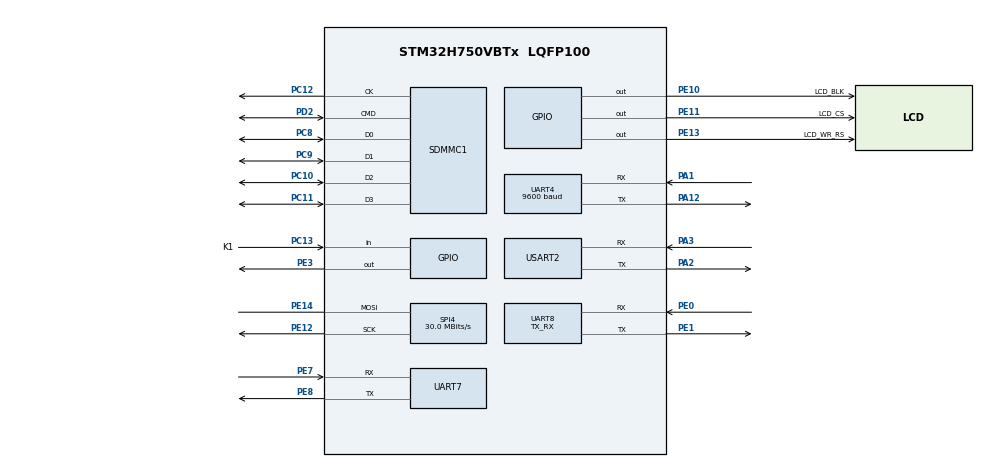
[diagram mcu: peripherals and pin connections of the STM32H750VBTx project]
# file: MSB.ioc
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CORTEX_M7.default_mode_Activation=1
Dma.Request0=UART8_TX
Dma.Request1=UART7_RX
Dma.Request2=UART4_TX
Dma.Request3=USART2_RX
Dma.UART4_TX.2.Direction=DMA_MEMORY_TO_PERIPH
Dma.UART4_TX.2.EventEnable=DISABLE
Dma.UART4_TX.2.FIFOMode=DMA_FIFOMODE_DISABLE
Dma.UART4_TX.2.Instance=DMA1_Stream3
Dma.UART4_TX.2.MemDataAlignment=DMA_MDATAALIGN_BYTE
Dma.UART4_TX.2.MemInc=DMA_MINC_ENABLE
Dma.UART4_TX.2.Mode=DMA_NORMAL
Dma.UART4_TX.2.PeriphDataAlignment=DMA_PDATAALIGN_BYTE
Dma.UART4_TX.2.PeriphInc=DMA_PINC_DISABLE
Dma.UART4_TX.2.Polarity=HAL_DMAMUX_REQ_GEN_RISING
Dma.UART4_TX.2.Priority=DMA_PRIORITY_LOW
Dma.UART4_TX.2.RequestNumber=1
Dma.UART4_TX.2.SignalID=NONE
Dma.UART4_TX.2.SyncEnable=DISABLE
Dma.UART4_TX.2.SyncPolarity=HAL_DMAMUX_SYNC_NO_EVENT
Dma.UART4_TX.2.SyncRequestNumber=1
Dma.UART4_TX.2.SyncSignalID=NONE
Dma.UART7_RX.1.Direction=DMA_PERIPH_TO_MEMORY
Dma.UART7_RX.1.EventEnable=DISABLE
Dma.UART7_RX.1.FIFOMode=DMA_FIFOMODE_DISABLE
Dma.UART7_RX.1.Instance=DMA1_Stream0
Dma.UART7_RX.1.MemDataAlignment=DMA_MDATAALIGN_BYTE
Dma.UART7_RX.1.MemInc=DMA_MINC_ENABLE
Dma.UART7_RX.1.Mode=DMA_CIRCULAR
Dma.UART7_RX.1.PeriphDataAlignment=DMA_PDATAALIGN_BYTE
Dma.UART7_RX.1.PeriphInc=DMA_PINC_DISABLE
Dma.UART7_RX.1.Polarity=HAL_DMAMUX_REQ_GEN_RISING
Dma.UART7_RX.1.Priority=DMA_PRIORITY_LOW
Dma.UART7_RX.1.RequestNumber=1
Dma.UART7_RX.1.SignalID=NONE
Dma.UART7_RX.1.SyncEnable=DISABLE
Dma.UART7_RX.1.SyncPolarity=HAL_DMAMUX_SYNC_NO_EVENT
Dma.UART7_RX.1.SyncRequestNumber=1
Dma.UART7_RX.1.SyncSignalID=NONE
Dma.UART8_TX.0.Direction=DMA_MEMORY_TO_PERIPH
Dma.UART8_TX.0.EventEnable=DISABLE
Dma.UART8_TX.0.FIFOMode=DMA_FIFOMODE_DISABLE
Dma.UART8_TX.0.Instance=DMA1_Stream1
Dma.UART8_TX.0.MemDataAlignment=DMA_MDATAALIGN_BYTE
Dma.UART8_TX.0.MemInc=DMA_MINC_ENABLE
Dma.UART8_TX.0.Mode=DMA_NORMAL
Dma.UART8_TX.0.PeriphDataAlignment=DMA_PDATAALIGN_BYTE
Dma.UART8_TX.0.PeriphInc=DMA_PINC_DISABLE
Dma.UART8_TX.0.Polarity=HAL_DMAMUX_REQ_GEN_RISING
Dma.UART8_TX.0.Priority=DMA_PRIORITY_VERY_HIGH
Dma.UART8_TX.0.RequestNumber=1
Dma.UART8_TX.0.SignalID=NONE
Dma.UART8_TX.0.SyncEnable=DISABLE
Dma.UART8_TX.0.SyncPolarity=HAL_DMAMUX_SYNC_NO_EVENT
Dma.UART8_TX.0.SyncRequestNumber=1
Dma.UART8_TX.0.SyncSignalID=NONE
Dma.USART2_RX.3.Direction=DMA_PERIPH_TO_MEMORY
Dma.USART2_RX.3.EventEnable=DISABLE
Dma.USART2_RX.3.FIFOMode=DMA_FIFOMODE_DISABLE
Dma.USART2_RX.3.Instance=DMA1_Stream2
Dma.USART2_RX.3.MemDataAlignment=DMA_MDATAALIGN_BYTE
Dma.USART2_RX.3.MemInc=DMA_MINC_ENABLE
Dma.USART2_RX.3.Mode=DMA_NORMAL
Dma.USART2_RX.3.PeriphDataAlignment=DMA_PDATAALIGN_BYTE
Dma.USART2_RX.3.PeriphInc=DMA_PINC_DISABLE
Dma.USART2_RX.3.Polarity=HAL_DMAMUX_REQ_GEN_RISING
Dma.USART2_RX.3.Priority=DMA_PRIORITY_LOW
Dma.USART2_RX.3.RequestNumber=1
Dma.USART2_RX.3.SignalID=NONE
Dma.USART2_RX.3.SyncEnable=DISABLE
Dma.USART2_RX.3.SyncPolarity=HAL_DMAMUX_SYNC_NO_EVENT
Dma.USART2_RX.3.SyncRequestNumber=1
Dma.USART2_RX.3.SyncSignalID=NONE
FATFS.USE_DMA_CODE_SD=1
FATFS._CODE_PAGE=936
FATFS._FS_EXFAT=1
FATFS._USE_LFN=2
Mcu.Family=STM32H7
Mcu.Name=STM32H750VBTx
Mcu.Package=LQFP100
NVIC.DMA1_Stream0_IRQn=true\:1\:0\:true\:false\:true\:false\:true\:true
NVIC.DMA1_Stream1_IRQn=true\:1\:1\:true\:false\:true\:false\:true\:true
NVIC.DMA1_Stream2_IRQn=true\:1\:0\:true\:false\:true\:false\:true\:true
NVIC.DMA1_Stream3_IRQn=true\:1\:0\:true\:false\:true\:false\:true\:true
NVIC.PriorityGroup=NVIC_PRIORITYGROUP_3
NVIC.SDMMC1_IRQn=true\:1\:0\:true\:false\:true\:true\:true\:true
NVIC.TIM15_IRQn=true\:1\:0\:true\:false\:true\:true\:true\:true
NVIC.TIM16_IRQn=true\:0\:0\:true\:false\:true\:true\:true\:true
NVIC.TIM17_IRQn=true\:3\:0\:true\:false\:true\:true\:true\:true
NVIC.TIM8_TRG_COM_TIM14_IRQn=true\:2\:0\:true\:false\:true\:true\:true\:true
NVIC.UART4_IRQn=true\:1\:0\:true\:false\:true\:true\:true\:true
NVIC.UART7_IRQn=true\:1\:0\:true\:false\:true\:true\:true\:true
NVIC.UART8_IRQn=true\:5\:0\:true\:false\:true\:false\:true\:true
NVIC.USART2_IRQn=true\:1\:0\:true\:false\:true\:true\:true\:true
PA1.Mode=Asynchronous
PA1.Signal=UART4_RX
PA12.Mode=Asynchronous
PA12.Signal=UART4_TX
PA13\ (JTMS/SWDIO).Mode=Serial_Wire
PA13\ (JTMS/SWDIO).Signal=DEBUG_JTMS-SWDIO
PA14\ (JTCK/SWCLK).Mode=Serial_Wire
PA14\ (JTCK/SWCLK).Signal=DEBUG_JTCK-SWCLK
PA2.Mode=Asynchronous
PA2.Signal=USART2_TX
PA3.Mode=Asynchronous
PA3.Signal=USART2_RX
PC10.Mode=SD_4_bits_Wide_bus
PC10.Signal=SDMMC1_D2
PC11.Mode=SD_4_bits_Wide_bus
PC11.Signal=SDMMC1_D3
PC12.Mode=SD_4_bits_Wide_bus
PC12.Signal=SDMMC1_CK
PC13.GPIO_Label=K1
PC13.GPIO_PuPd=GPIO_PULLDOWN
PC13.Signal=GPIO_Input
PC8.Mode=SD_4_bits_Wide_bus
PC8.Signal=SDMMC1_D0
PC9.Mode=SD_4_bits_Wide_bus
PC9.Signal=SDMMC1_D1
PD2.Mode=SD_4_bits_Wide_bus
PD2.Signal=SDMMC1_CMD
PE0.Mode=Asynchronous
PE0.Signal=UART8_RX
PE1.Mode=Asynchronous
PE1.Signal=UART8_TX
PE10.GPIO_Label=LCD_BLK
PE10.Signal=GPIO_Output
PE11.GPIO_Label=LCD_CS
PE11.Signal=GPIO_Output
PE12.Mode=Simplex_Bidirectional_Master
PE12.Signal=SPI4_SCK
PE13.GPIO_Label=LCD_WR_RS
PE13.Signal=GPIO_Output
PE14.Mode=Simplex_Bidirectional_Master
PE14.Signal=SPI4_MOSI
PE3.Signal=GPIO_Output
PE7.Mode=Asynchronous
PE7.Signal=UART7_RX
PE8.Mode=Asynchronous
PE8.Signal=UART7_TX
PH0-OSC_IN\ (PH0).Mode=HSE-External-Oscillator
PH0-OSC_IN\ (PH0).Signal=RCC_OSC_IN
PH1-OSC_OUT\ (PH1).Mode=HSE-External-Oscillator
PH1-OSC_OUT\ (PH1).Signal=RCC_OSC_OUT
ProjectManager.HeapSize=0x2000
ProjectManager.StackSize=0x8000
ProjectManager.TargetToolchain=CMake
RCC.ADCFreq_Value=50390625
RCC.APB1Freq_Value=120000000
RCC.APB2Freq_Value=120000000
RCC.APB3Freq_Value=120000000
RCC.APB4Freq_Value=120000000
RCC.CortexFreq_Value=480000000
RCC.D1PPRE=RCC_APB3_DIV2
RCC.D2PPRE1=RCC_APB1_DIV2
RCC.D2PPRE2=RCC_APB2_DIV2
RCC.D3PPRE=RCC_APB4_DIV2
RCC.DIVM1=5
RCC.DIVN1=192
RCC.DIVQ1=15
RCC.HCLKFreq_Value=240000000
RCC.HPRE=RCC_HCLK_DIV2
RCC.PLLFRACN=0
RCC.PLLSourceVirtual=RCC_PLLSOURCE_HSE
RCC.SYSCLKFreq_VALUE=480000000
RCC.SYSCLKSource=RCC_SYSCLKSOURCE_PLLCLK
RCC.USBFreq_Value=64000000
SDMMC1.ClockDiv=5
SPI4.BaudRatePrescaler=SPI_BAUDRATEPRESCALER_4
SPI4.CalculateBaudRate=30.0 MBits/s
SPI4.DataSize=SPI_DATASIZE_8BIT
SPI4.Direction=SPI_DIRECTION_1LINE
SPI4.Mode=SPI_MODE_MASTER
SPI4.VirtualType=VM_MASTER
TIM14.Period=5000-1
TIM14.Prescaler=240-1
TIM15.Period=1000-1
TIM15.Prescaler=480-1
TIM16.Period=1000-1
TIM16.Prescaler=240-1
TIM17.Period=10000-1
TIM17.Prescaler=2400-1
UART4.BaudRate=9600
UART4.ClockPrescaler=PRESCALER_DIV10
UART4.SwapParam=UART_ADVFEATURE_SWAP_DISABLE
UART7.RXFIFOThreshold=RXFIFO_THRESHOLD_HALFFULL
UART7.TXFIFOThreshold=TXFIFO_THRESHOLD_HALFFULL
UART8.FIFOMode=FIFOMODE_ENABLE
UART8.Mode=MODE_TX_RX
UART8.RXFIFOThreshold=RXFIFO_THRESHOLD_HALFFULL
UART8.SwapParam=UART_ADVFEATURE_SWAP_ENABLE
UART8.TXFIFOThreshold=TXFIFO_THRESHOLD_HALFFULL
USART2.SwapParam=ADVFEATURE_SWAP_ENABLE
USART2.VirtualMode-Asynchronous=VM_ASYNC
VP_FATFS_VS_SDIO.Mode=SDIO
VP_MEMORYMAP_VS_MEMORYMAP.Mode=CurAppReg
VP_TIM14_VS_ClockSourceINT.Mode=Enable_Timer
VP_TIM15_VS_ClockSourceINT.Mode=Internal
VP_TIM16_VS_ClockSourceINT.Mode=Enable_Timer
VP_TIM17_VS_ClockSourceINT.Mode=Enable_Timer
board=custom

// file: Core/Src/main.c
/* USER CODE BEGIN Header */
/**
  ******************************************************************************
  * @file           : main.c
  * @brief          : Main program body
  ******************************************************************************
  * @attention
  *
  * Copyright (c) 2025 STMicroelectronics.
  * All rights reserved.
  *
  * This software is licensed under terms that can be found in the LICENSE file
  * in the root directory of this software component.
  * If no LICENSE file comes with this software, it is provided AS-IS.
  *
  ******************************************************************************
  */
/* USER CODE END Header */
#include "main.h"
#include "dma.h"
#include "fatfs.h"
#include "sdmmc.h"
#include "spi.h"
#include "tim.h"
#include "usart.h"
#include "gpio.h"

/* USER CODE BEGIN Includes */
#include "delay/delay.h"
#include "yuntai.h"
#include "control.h"
#include "HCI.h"
#include "TFT18_ST7735S.h"
#include "DMR4315.h"
/* USER CODE END Includes */

void SystemClock_Config(void);
static void MPU_Config(void);
/* USER CODE BEGIN PFP */
int user_main(void);
/* USER CODE END PFP */

int main(void)
{

  /* MPU Configuration--------------------------------------------------------*/
  MPU_Config();

  /* MCU Configuration--------------------------------------------------------*/

  /* Reset of all peripherals, Initializes the Flash interface and the Systick. */
  HAL_Init();

  /* Configure the system clock */
  SystemClock_Config();

  /* USER CODE BEGIN SysInit */
    delay_init(480);
  /* USER CODE END SysInit */

  /* Initialize all configured peripherals */
  MX_GPIO_Init();
  MX_DMA_Init();
  MX_UART8_Init();
  MX_UART7_Init();
  MX_TIM15_Init();
  MX_SPI4_Init();
  MX_TIM17_Init();
  MX_TIM16_Init();
  MX_TIM14_Init();
  MX_USART2_UART_Init();
  MX_UART4_Init();
  MX_SDMMC1_SD_Init();
  MX_FATFS_Init();
  /* USER CODE BEGIN 2 */
    /********* user init begin *********/
    user_main();
    /********* user init end *********/
  /* USER CODE END 2 */

  /* Infinite loop */
  /* USER CODE BEGIN WHILE */
    //yuntai_set_flag(PID_CONTROL_FLAG);
    //yuntai_set_flag(MOTOR_PARAM_FLAG);

    while (1) {
    /* USER CODE END WHILE */

    }
}

void SystemClock_Config(void)
{
  RCC_OscInitTypeDef RCC_OscInitStruct = {0};
  RCC_ClkInitTypeDef RCC_ClkInitStruct = {0};

  /** Supply configuration update enable
  */
  HAL_PWREx_ConfigSupply(PWR_LDO_SUPPLY);

  /** Configure the main internal regulator output voltage
  */
  __HAL_PWR_VOLTAGESCALING_CONFIG(PWR_REGULATOR_VOLTAGE_SCALE0);

  while(!__HAL_PWR_GET_FLAG(PWR_FLAG_VOSRDY)) {}

  /** Initializes the RCC Oscillators according to the specified parameters
  * in the RCC_OscInitTypeDef structure.
  */
  RCC_OscInitStruct.OscillatorType = RCC_OSCILLATORTYPE_HSE;
  RCC_OscInitStruct.HSEState = RCC_HSE_ON;
  RCC_OscInitStruct.PLL.PLLState = RCC_PLL_ON;
  RCC_OscInitStruct.PLL.PLLSource = RCC_PLLSOURCE_HSE;
  RCC_OscInitStruct.PLL.PLLM = 5;
  RCC_OscInitStruct.PLL.PLLN = 192;
  RCC_OscInitStruct.PLL.PLLP = 2;
  RCC_OscInitStruct.PLL.PLLQ = 15;
  RCC_OscInitStruct.PLL.PLLR = 2;
  RCC_OscInitStruct.PLL.PLLRGE = RCC_PLL1VCIRANGE_2;
  RCC_OscInitStruct.PLL.PLLVCOSEL = RCC_PLL1VCOWIDE;
  RCC_OscInitStruct.PLL.PLLFRACN = 0;
  if (HAL_RCC_OscConfig(&RCC_OscInitStruct) != HAL_OK)
  {
    Error_Handler();
  }

  /** Initializes the CPU, AHB and APB buses clocks
  */
  RCC_ClkInitStruct.ClockType = RCC_CLOCKTYPE_HCLK|RCC_CLOCKTYPE_SYSCLK
                              |RCC_CLOCKTYPE_PCLK1|RCC_CLOCKTYPE_PCLK2
                              |RCC_CLOCKTYPE_D3PCLK1|RCC_CLOCKTYPE_D1PCLK1;
  RCC_ClkInitStruct.SYSCLKSource = RCC_SYSCLKSOURCE_PLLCLK;
  RCC_ClkInitStruct.SYSCLKDivider = RCC_SYSCLK_DIV1;
  RCC_ClkInitStruct.AHBCLKDivider = RCC_HCLK_DIV2;
  RCC_ClkInitStruct.APB3CLKDivider = RCC_APB3_DIV2;
  RCC_ClkInitStruct.APB1CLKDivider = RCC_APB1_DIV2;
  RCC_ClkInitStruct.APB2CLKDivider = RCC_APB2_DIV2;
  RCC_ClkInitStruct.APB4CLKDivider = RCC_APB4_DIV2;

  if (HAL_RCC_ClockConfig(&RCC_ClkInitStruct, FLASH_LATENCY_4) != HAL_OK)
  {
    Error_Handler();
  }
}

 /* MPU Configuration */

void MPU_Config(void)
{
  MPU_Region_InitTypeDef MPU_InitStruct = {0};

  /* Disables the MPU */
  HAL_MPU_Disable();

  /** Initializes and configures the Region and the memory to be protected
  */
  MPU_InitStruct.Enable = MPU_REGION_ENABLE;
  MPU_InitStruct.Number = MPU_REGION_NUMBER0;
  MPU_InitStruct.BaseAddress = 0x0;
  MPU_InitStruct.Size = MPU_REGION_SIZE_4GB;
  MPU_InitStruct.SubRegionDisable = 0x87;
  MPU_InitStruct.TypeExtField = MPU_TEX_LEVEL0;
  MPU_InitStruct.AccessPermission = MPU_REGION_NO_ACCESS;
  MPU_InitStruct.DisableExec = MPU_INSTRUCTION_ACCESS_DISABLE;
  MPU_InitStruct.IsShareable = MPU_ACCESS_SHAREABLE;
  MPU_InitStruct.IsCacheable = MPU_ACCESS_NOT_CACHEABLE;
  MPU_InitStruct.IsBufferable = MPU_ACCESS_NOT_BUFFERABLE;

  HAL_MPU_ConfigRegion(&MPU_InitStruct);
  /* Enables the MPU */
  HAL_MPU_Enable(MPU_PRIVILEGED_DEFAULT);

}

void Error_Handler(void)
{
  /* USER CODE BEGIN Error_Handler_Debug */
    TFTSPI_Init();
    TFTSPI_CLS(COLOR_RED);
    TFT_Printf(0, 0, COLOR_WHITE,COLOR_RED, fsize_8X16, "%5s", "Error Handler:");
    TFT_Printf(0, 17, COLOR_WHITE,COLOR_RED, fsize_6X8, "%5s", "Check BSP_init");
    TFT_Printf(0, 28, COLOR_WHITE,COLOR_RED, fsize_6X8, "%5s", "Check SD/FatFs");
    /* User can add his own implementation to report the HAL error return state */
    __disable_irq();
    while (1) {
    }
  /* USER CODE END Error_Handler_Debug */
}
